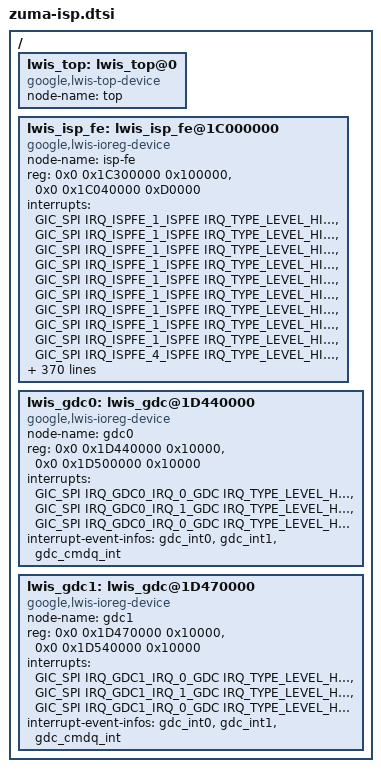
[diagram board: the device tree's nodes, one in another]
// SPDX-License-Identifier: GPL-2.0-only
/*
 * Zuma camera ISP device tree source
 *
 * Copyright 2022 Google LLC.
 */

#include <dt-bindings/interrupt-controller/irq.h>
#include <dt-bindings/interrupt-controller/arm-gic.h>
#include <dt-bindings/interrupt-controller/zuma.h>
#include "zuma-isp-event-info.dtsi"

/ {
	lwis_top: lwis_top@0 {
		compatible = "google,lwis-top-device";

		/* Device node name */
		node-name = "top";
	};

	lwis_isp_fe: lwis_isp_fe@1C000000 {
		compatible = "google,lwis-ioreg-device";

		/* Device node name */
		node-name = "isp-fe";

		/* Register space */
		reg =
			<0x0 0x1C300000 0x100000>, /* ISPFE */
			<0x0 0x1C040000 0xD0000>;  /* CSIS LINK & PHY*/
		reg-names =
			"isp-fe",
			"csis-link-phy";

		interrupts =
			<GIC_SPI IRQ_ISPFE_1_ISPFE IRQ_TYPE_LEVEL_HIGH>
			<GIC_SPI IRQ_ISPFE_1_ISPFE IRQ_TYPE_LEVEL_HIGH>
			<GIC_SPI IRQ_ISPFE_1_ISPFE IRQ_TYPE_LEVEL_HIGH>
			<GIC_SPI IRQ_ISPFE_1_ISPFE IRQ_TYPE_LEVEL_HIGH>
			<GIC_SPI IRQ_ISPFE_1_ISPFE IRQ_TYPE_LEVEL_HIGH>
			<GIC_SPI IRQ_ISPFE_1_ISPFE IRQ_TYPE_LEVEL_HIGH>
			<GIC_SPI IRQ_ISPFE_1_ISPFE IRQ_TYPE_LEVEL_HIGH>
			<GIC_SPI IRQ_ISPFE_1_ISPFE IRQ_TYPE_LEVEL_HIGH>
			<GIC_SPI IRQ_ISPFE_1_ISPFE IRQ_TYPE_LEVEL_HIGH>
			<GIC_SPI IRQ_ISPFE_4_ISPFE IRQ_TYPE_LEVEL_HIGH>
			<GIC_SPI IRQ_ISPFE_4_ISPFE IRQ_TYPE_LEVEL_HIGH>
			<GIC_SPI IRQ_ISPFE_4_ISPFE IRQ_TYPE_LEVEL_HIGH>
			<GIC_SPI IRQ_ISPFE_4_ISPFE IRQ_TYPE_LEVEL_HIGH>
			<GIC_SPI IRQ_ISPFE_4_ISPFE IRQ_TYPE_LEVEL_HIGH>
			<GIC_SPI IRQ_ISPFE_4_ISPFE IRQ_TYPE_LEVEL_HIGH>
			<GIC_SPI IRQ_ISPFE_4_ISPFE IRQ_TYPE_LEVEL_HIGH>
			<GIC_SPI IRQ_ISPFE_4_ISPFE IRQ_TYPE_LEVEL_HIGH>
			<GIC_SPI IRQ_ISPFE_4_ISPFE IRQ_TYPE_LEVEL_HIGH>
			<GIC_SPI IRQ_ISPFE_4_ISPFE IRQ_TYPE_LEVEL_HIGH>
			<GIC_SPI IRQ_ISPFE_4_ISPFE IRQ_TYPE_LEVEL_HIGH>
			<GIC_SPI IRQ_ISPFE_4_ISPFE IRQ_TYPE_LEVEL_HIGH>
			<GIC_SPI IRQ_ISPFE_4_ISPFE IRQ_TYPE_LEVEL_HIGH>
			<GIC_SPI IRQ_ISPFE_4_ISPFE IRQ_TYPE_LEVEL_HIGH>
			<GIC_SPI IRQ_ISPFE_4_ISPFE IRQ_TYPE_LEVEL_HIGH>
			<GIC_SPI IRQ_ISPFE_2_ISPFE IRQ_TYPE_LEVEL_HIGH>
			<GIC_SPI IRQ_ISPFE_2_ISPFE IRQ_TYPE_LEVEL_HIGH>
			<GIC_SPI IRQ_ISPFE_2_ISPFE IRQ_TYPE_LEVEL_HIGH>
			<GIC_SPI IRQ_ISPFE_2_ISPFE IRQ_TYPE_LEVEL_HIGH>
			<GIC_SPI IRQ_ISPFE_2_ISPFE IRQ_TYPE_LEVEL_HIGH>
			<GIC_SPI IRQ_ISPFE_3_ISPFE IRQ_TYPE_LEVEL_HIGH>
			<GIC_SPI IRQ_ISPFE_3_ISPFE IRQ_TYPE_LEVEL_HIGH>
			<GIC_SPI IRQ_ISPFE_3_ISPFE IRQ_TYPE_LEVEL_HIGH>
			<GIC_SPI IRQ_ISPFE_3_ISPFE IRQ_TYPE_LEVEL_HIGH>
			<GIC_SPI IRQ_ISPFE_2_ISPFE IRQ_TYPE_LEVEL_HIGH>
			<GIC_SPI IRQ_ISPFE_0_ISPFE IRQ_TYPE_LEVEL_HIGH>
			<GIC_SPI IRQ_ISPFE_0_ISPFE IRQ_TYPE_LEVEL_HIGH>
			<GIC_SPI IRQ_ISPFE_0_ISPFE IRQ_TYPE_LEVEL_HIGH>
			<GIC_SPI IRQ_ISPFE_0_ISPFE IRQ_TYPE_LEVEL_HIGH>
			<GIC_SPI IRQ_ISPFE_0_ISPFE IRQ_TYPE_LEVEL_HIGH>
			<GIC_SPI IRQ_ISPFE_0_ISPFE IRQ_TYPE_LEVEL_HIGH>
			<GIC_SPI IRQ_ISPFE_0_ISPFE IRQ_TYPE_LEVEL_HIGH>
			<GIC_SPI IRQ_ISPFE_0_ISPFE IRQ_TYPE_LEVEL_HIGH>
			<GIC_SPI IRQ_ISPFE_0_ISPFE IRQ_TYPE_LEVEL_HIGH>
			<GIC_SPI IRQ_ISPFE_0_ISPFE IRQ_TYPE_LEVEL_HIGH>
			<GIC_SPI IRQ_ISPFE_0_ISPFE IRQ_TYPE_LEVEL_HIGH>
			<GIC_SPI IRQ_ISPFE_0_ISPFE IRQ_TYPE_LEVEL_HIGH>
			<GIC_SPI IRQ_ISPFE_0_ISPFE IRQ_TYPE_LEVEL_HIGH>
			<GIC_SPI IRQ_ISPFE_0_ISPFE IRQ_TYPE_LEVEL_HIGH>
			<GIC_SPI IRQ_ISPFE_0_ISPFE IRQ_TYPE_LEVEL_HIGH>
			<GIC_SPI IRQ_ISPFE_0_ISPFE IRQ_TYPE_LEVEL_HIGH>
			<GIC_SPI IRQ_ISPFE_0_ISPFE IRQ_TYPE_LEVEL_HIGH>
			<GIC_SPI IRQ_ISPFE_0_ISPFE IRQ_TYPE_LEVEL_HIGH>
			<GIC_SPI IRQ_ISPFE_0_ISPFE IRQ_TYPE_LEVEL_HIGH>
			<GIC_SPI IRQ_ISPFE_0_ISPFE IRQ_TYPE_LEVEL_HIGH>
			<GIC_SPI IRQ_ISPFE_0_ISPFE IRQ_TYPE_LEVEL_HIGH>
			<GIC_SPI IRQ_ISPFE_0_ISPFE IRQ_TYPE_LEVEL_HIGH>
			<GIC_SPI IRQ_ISPFE_0_ISPFE IRQ_TYPE_LEVEL_HIGH>
			<GIC_SPI IRQ_ISPFE_0_ISPFE IRQ_TYPE_LEVEL_HIGH>
			<GIC_SPI IRQ_ISPFE_0_ISPFE IRQ_TYPE_LEVEL_HIGH>
			<GIC_SPI IRQ_ISPFE_0_ISPFE IRQ_TYPE_LEVEL_HIGH>
			<GIC_SPI IRQ_ISPFE_0_ISPFE IRQ_TYPE_LEVEL_HIGH>
			<GIC_SPI IRQ_ISPFE_0_ISPFE IRQ_TYPE_LEVEL_HIGH>
			<GIC_SPI IRQ_ISPFE_0_ISPFE IRQ_TYPE_LEVEL_HIGH>
			<GIC_SPI IRQ_ISPFE_0_ISPFE IRQ_TYPE_LEVEL_HIGH>
			<GIC_SPI IRQ_ISPFE_0_ISPFE IRQ_TYPE_LEVEL_HIGH>
			<GIC_SPI IRQ_ISPFE_0_ISPFE IRQ_TYPE_LEVEL_HIGH>
			<GIC_SPI IRQ_ISPFE_0_ISPFE IRQ_TYPE_LEVEL_HIGH>
			<GIC_SPI IRQ_ISPFE_0_ISPFE IRQ_TYPE_LEVEL_HIGH>
			<GIC_SPI IRQ_ISPFE_0_ISPFE IRQ_TYPE_LEVEL_HIGH>
			<GIC_SPI IRQ_ISPFE_0_ISPFE IRQ_TYPE_LEVEL_HIGH>
			<GIC_SPI IRQ_ISPFE_0_ISPFE IRQ_TYPE_LEVEL_HIGH>
			<GIC_SPI IRQ_ISPFE_0_ISPFE IRQ_TYPE_LEVEL_HIGH>
			<GIC_SPI IRQ_ISPFE_0_ISPFE IRQ_TYPE_LEVEL_HIGH>
			<GIC_SPI IRQ_ISPFE_0_ISPFE IRQ_TYPE_LEVEL_HIGH>
			<GIC_SPI IRQ_ISPFE_0_ISPFE IRQ_TYPE_LEVEL_HIGH>
			<GIC_SPI IRQ_ISPFE_0_ISPFE IRQ_TYPE_LEVEL_HIGH>
			<GIC_SPI IRQ_ISPFE_0_ISPFE IRQ_TYPE_LEVEL_HIGH>
			<GIC_SPI IRQ_ISPFE_0_ISPFE IRQ_TYPE_LEVEL_HIGH>
			<GIC_SPI IRQ_ISPFE_0_ISPFE IRQ_TYPE_LEVEL_HIGH>
			<GIC_SPI IRQ_ISPFE_0_ISPFE IRQ_TYPE_LEVEL_HIGH>
			<GIC_SPI IRQ_ISPFE_0_ISPFE IRQ_TYPE_LEVEL_HIGH>
			<GIC_SPI IRQ_ISPFE_0_ISPFE IRQ_TYPE_LEVEL_HIGH>
			<GIC_SPI IRQ_ISPFE_0_ISPFE IRQ_TYPE_LEVEL_HIGH>
			<GIC_SPI IRQ_ISPFE_0_ISPFE IRQ_TYPE_LEVEL_HIGH>
			<GIC_SPI IRQ_ISPFE_0_ISPFE IRQ_TYPE_LEVEL_HIGH>
			<GIC_SPI IRQ_ISPFE_0_ISPFE IRQ_TYPE_LEVEL_HIGH>
			<GIC_SPI IRQ_ISPFE_0_ISPFE IRQ_TYPE_LEVEL_HIGH>
			<GIC_SPI IRQ_ISPFE_0_ISPFE IRQ_TYPE_LEVEL_HIGH>
			<GIC_SPI IRQ_ISPFE_0_ISPFE IRQ_TYPE_LEVEL_HIGH>
			<GIC_SPI IRQ_ISPFE_0_ISPFE IRQ_TYPE_LEVEL_HIGH>
			<GIC_SPI IRQ_ISPFE_0_ISPFE IRQ_TYPE_LEVEL_HIGH>
			<GIC_SPI IRQ_ISPFE_0_ISPFE IRQ_TYPE_LEVEL_HIGH>
			<GIC_SPI IRQ_ISPFE_0_ISPFE IRQ_TYPE_LEVEL_HIGH>
			<GIC_SPI IRQ_ISPFE_0_ISPFE IRQ_TYPE_LEVEL_HIGH>
			<GIC_SPI IRQ_ISPFE_0_ISPFE IRQ_TYPE_LEVEL_HIGH>
			<GIC_SPI IRQ_ISPFE_0_ISPFE IRQ_TYPE_LEVEL_HIGH>
			<GIC_SPI IRQ_ISPFE_0_ISPFE IRQ_TYPE_LEVEL_HIGH>
			<GIC_SPI IRQ_ISPFE_0_ISPFE IRQ_TYPE_LEVEL_HIGH>
			<GIC_SPI IRQ_ISPFE_0_ISPFE IRQ_TYPE_LEVEL_HIGH>
			<GIC_SPI IRQ_ISPFE_0_ISPFE IRQ_TYPE_LEVEL_HIGH>
			<GIC_SPI IRQ_ISPFE_0_ISPFE IRQ_TYPE_LEVEL_HIGH>
			<GIC_SPI IRQ_ISPFE_0_ISPFE IRQ_TYPE_LEVEL_HIGH>
			<GIC_SPI IRQ_ISPFE_0_ISPFE IRQ_TYPE_LEVEL_HIGH>
			<GIC_SPI IRQ_ISPFE_0_ISPFE IRQ_TYPE_LEVEL_HIGH>
			<GIC_SPI IRQ_ISPFE_0_ISPFE IRQ_TYPE_LEVEL_HIGH>
			<GIC_SPI IRQ_ISPFE_0_ISPFE IRQ_TYPE_LEVEL_HIGH>
			<GIC_SPI IRQ_ISPFE_0_ISPFE IRQ_TYPE_LEVEL_HIGH>
			<GIC_SPI IRQ_ISPFE_0_ISPFE IRQ_TYPE_LEVEL_HIGH>
			<GIC_SPI IRQ_ISPFE_0_ISPFE IRQ_TYPE_LEVEL_HIGH>
			<GIC_SPI IRQ_ISPFE_0_ISPFE IRQ_TYPE_LEVEL_HIGH>
			<GIC_SPI IRQ_ISPFE_0_ISPFE IRQ_TYPE_LEVEL_HIGH>
			<GIC_SPI IRQ_ISPFE_0_ISPFE IRQ_TYPE_LEVEL_HIGH>
			<GIC_SPI IRQ_ISPFE_0_ISPFE IRQ_TYPE_LEVEL_HIGH>
			<GIC_SPI IRQ_ISPFE_0_ISPFE IRQ_TYPE_LEVEL_HIGH>
			<GIC_SPI IRQ_ISPFE_0_ISPFE IRQ_TYPE_LEVEL_HIGH>
			<GIC_SPI IRQ_ISPFE_0_ISPFE IRQ_TYPE_LEVEL_HIGH>
			<GIC_SPI IRQ_ISPFE_0_ISPFE IRQ_TYPE_LEVEL_HIGH>
			<GIC_SPI IRQ_ISPFE_0_ISPFE IRQ_TYPE_LEVEL_HIGH>
			<GIC_SPI IRQ_ISPFE_0_ISPFE IRQ_TYPE_LEVEL_HIGH>
			<GIC_SPI IRQ_ISPFE_0_ISPFE IRQ_TYPE_LEVEL_HIGH>
			<GIC_SPI IRQ_ISPFE_0_ISPFE IRQ_TYPE_LEVEL_HIGH>
			<GIC_SPI IRQ_ISPFE_0_ISPFE IRQ_TYPE_LEVEL_HIGH>
			<GIC_SPI IRQ_ISPFE_0_ISPFE IRQ_TYPE_LEVEL_HIGH>
			<GIC_SPI IRQ_ISPFE_0_ISPFE IRQ_TYPE_LEVEL_HIGH>
			<GIC_SPI IRQ_ISPFE_0_ISPFE IRQ_TYPE_LEVEL_HIGH>
			<GIC_SPI IRQ_ISPFE_0_ISPFE IRQ_TYPE_LEVEL_HIGH>
			<GIC_SPI IRQ_ISPFE_0_ISPFE IRQ_TYPE_LEVEL_HIGH>
			<GIC_SPI IRQ_ISPFE_0_ISPFE IRQ_TYPE_LEVEL_HIGH>
			<GIC_SPI IRQ_ISPFE_0_ISPFE IRQ_TYPE_LEVEL_HIGH>
			<GIC_SPI IRQ_ISPFE_0_ISPFE IRQ_TYPE_LEVEL_HIGH>
			<GIC_SPI IRQ_ISPFE_0_ISPFE IRQ_TYPE_LEVEL_HIGH>
			<GIC_SPI IRQ_ISPFE_0_ISPFE IRQ_TYPE_LEVEL_HIGH>
			<GIC_SPI IRQ_ISPFE_0_ISPFE IRQ_TYPE_LEVEL_HIGH>
			<GIC_SPI IRQ_ISPFE_0_ISPFE IRQ_TYPE_LEVEL_HIGH>
			<GIC_SPI IRQ_ISPFE_0_ISPFE IRQ_TYPE_LEVEL_HIGH>
			<GIC_SPI IRQ_ISPFE_0_ISPFE IRQ_TYPE_LEVEL_HIGH>
			<GIC_SPI IRQ_ISPFE_0_ISPFE IRQ_TYPE_LEVEL_HIGH>
			<GIC_SPI IRQ_ISPFE_0_ISPFE IRQ_TYPE_LEVEL_HIGH>
			<GIC_SPI IRQ_ISPFE_0_ISPFE IRQ_TYPE_LEVEL_HIGH>
			<GIC_SPI IRQ_ISPFE_0_ISPFE IRQ_TYPE_LEVEL_HIGH>
			<GIC_SPI IRQ_ISPFE_0_ISPFE IRQ_TYPE_LEVEL_HIGH>
			<GIC_SPI IRQ_ISPFE_0_ISPFE IRQ_TYPE_LEVEL_HIGH>
			<GIC_SPI IRQ_ISPFE_0_ISPFE IRQ_TYPE_LEVEL_HIGH>
			<GIC_SPI IRQ_ISPFE_0_ISPFE IRQ_TYPE_LEVEL_HIGH>
			<GIC_SPI IRQ_ISPFE_0_ISPFE IRQ_TYPE_LEVEL_HIGH>
			<GIC_SPI IRQ_ISPFE_0_ISPFE IRQ_TYPE_LEVEL_HIGH>
			<GIC_SPI IRQ_ISPFE_0_ISPFE IRQ_TYPE_LEVEL_HIGH>
			<GIC_SPI IRQ_ISPFE_0_ISPFE IRQ_TYPE_LEVEL_HIGH>
			<GIC_SPI IRQ_ISPFE_0_ISPFE IRQ_TYPE_LEVEL_HIGH>
			<GIC_SPI IRQ_ISPFE_0_ISPFE IRQ_TYPE_LEVEL_HIGH>
			<GIC_SPI IRQ_ISPFE_0_ISPFE IRQ_TYPE_LEVEL_HIGH>
			<GIC_SPI IRQ_ISPFE_0_ISPFE IRQ_TYPE_LEVEL_HIGH>
			<GIC_SPI IRQ_ISPFE_0_ISPFE IRQ_TYPE_LEVEL_HIGH>
			<GIC_SPI IRQ_ISPFE_0_ISPFE IRQ_TYPE_LEVEL_HIGH>
			<GIC_SPI IRQ_CSIS0_ISPFE IRQ_TYPE_LEVEL_HIGH>
			<GIC_SPI IRQ_CSIS1_ISPFE IRQ_TYPE_LEVEL_HIGH>
			<GIC_SPI IRQ_CSIS2_ISPFE IRQ_TYPE_LEVEL_HIGH>
			<GIC_SPI IRQ_CSIS3_ISPFE IRQ_TYPE_LEVEL_HIGH>
			<GIC_SPI IRQ_CSIS4_ISPFE IRQ_TYPE_LEVEL_HIGH>
			<GIC_SPI IRQ_CSIS5_ISPFE IRQ_TYPE_LEVEL_HIGH>
			<GIC_SPI IRQ_CSIS6_ISPFE IRQ_TYPE_LEVEL_HIGH>
			<GIC_SPI IRQ_CSIS7_ISPFE IRQ_TYPE_LEVEL_HIGH>
			<GIC_SPI IRQ_CSIS8_ISPFE IRQ_TYPE_LEVEL_HIGH>
			<GIC_SPI IRQ_CSIS9_ISPFE IRQ_TYPE_LEVEL_HIGH>
			<GIC_SPI IRQ_CSIS10_ISPFE IRQ_TYPE_LEVEL_HIGH>
			<GIC_SPI IRQ_CSIS11_ISPFE IRQ_TYPE_LEVEL_HIGH>
			<GIC_SPI IRQ_CSIS0_ISPFE IRQ_TYPE_LEVEL_HIGH>
			<GIC_SPI IRQ_CSIS1_ISPFE IRQ_TYPE_LEVEL_HIGH>
			<GIC_SPI IRQ_CSIS2_ISPFE IRQ_TYPE_LEVEL_HIGH>
			<GIC_SPI IRQ_CSIS3_ISPFE IRQ_TYPE_LEVEL_HIGH>
			<GIC_SPI IRQ_CSIS4_ISPFE IRQ_TYPE_LEVEL_HIGH>
			<GIC_SPI IRQ_CSIS5_ISPFE IRQ_TYPE_LEVEL_HIGH>
			<GIC_SPI IRQ_CSIS6_ISPFE IRQ_TYPE_LEVEL_HIGH>
			<GIC_SPI IRQ_CSIS7_ISPFE IRQ_TYPE_LEVEL_HIGH>
			<GIC_SPI IRQ_CSIS8_ISPFE IRQ_TYPE_LEVEL_HIGH>
			<GIC_SPI IRQ_CSIS9_ISPFE IRQ_TYPE_LEVEL_HIGH>
			<GIC_SPI IRQ_CSIS10_ISPFE IRQ_TYPE_LEVEL_HIGH>
			<GIC_SPI IRQ_CSIS11_ISPFE IRQ_TYPE_LEVEL_HIGH>
			<GIC_SPI IRQ_CSIS0_ISPFE IRQ_TYPE_LEVEL_HIGH>
			<GIC_SPI IRQ_CSIS1_ISPFE IRQ_TYPE_LEVEL_HIGH>
			<GIC_SPI IRQ_CSIS2_ISPFE IRQ_TYPE_LEVEL_HIGH>
			<GIC_SPI IRQ_CSIS3_ISPFE IRQ_TYPE_LEVEL_HIGH>
			<GIC_SPI IRQ_CSIS4_ISPFE IRQ_TYPE_LEVEL_HIGH>
			<GIC_SPI IRQ_CSIS5_ISPFE IRQ_TYPE_LEVEL_HIGH>
			<GIC_SPI IRQ_CSIS6_ISPFE IRQ_TYPE_LEVEL_HIGH>
			<GIC_SPI IRQ_CSIS7_ISPFE IRQ_TYPE_LEVEL_HIGH>
			<GIC_SPI IRQ_CSIS8_ISPFE IRQ_TYPE_LEVEL_HIGH>
			<GIC_SPI IRQ_CSIS9_ISPFE IRQ_TYPE_LEVEL_HIGH>
			<GIC_SPI IRQ_CSIS10_ISPFE IRQ_TYPE_LEVEL_HIGH>
			<GIC_SPI IRQ_CSIS11_ISPFE IRQ_TYPE_LEVEL_HIGH>
			<GIC_SPI IRQ_CSIS0_ISPFE IRQ_TYPE_LEVEL_HIGH>
			<GIC_SPI IRQ_CSIS1_ISPFE IRQ_TYPE_LEVEL_HIGH>
			<GIC_SPI IRQ_CSIS2_ISPFE IRQ_TYPE_LEVEL_HIGH>
			<GIC_SPI IRQ_CSIS3_ISPFE IRQ_TYPE_LEVEL_HIGH>
			<GIC_SPI IRQ_CSIS4_ISPFE IRQ_TYPE_LEVEL_HIGH>
			<GIC_SPI IRQ_CSIS5_ISPFE IRQ_TYPE_LEVEL_HIGH>
			<GIC_SPI IRQ_CSIS6_ISPFE IRQ_TYPE_LEVEL_HIGH>
			<GIC_SPI IRQ_CSIS7_ISPFE IRQ_TYPE_LEVEL_HIGH>
			<GIC_SPI IRQ_CSIS8_ISPFE IRQ_TYPE_LEVEL_HIGH>
			<GIC_SPI IRQ_CSIS9_ISPFE IRQ_TYPE_LEVEL_HIGH>
			<GIC_SPI IRQ_CSIS10_ISPFE IRQ_TYPE_LEVEL_HIGH>
			<GIC_SPI IRQ_CSIS11_ISPFE IRQ_TYPE_LEVEL_HIGH>;
		interrupt-names =
			"isp_fe_ctx0_fc_bayer",
			"isp_fe_ctx1_fc_bayer",
			"isp_fe_ctx2_fc_bayer",
			"isp_fe_ctx3_fc_bayer",
			"isp_fe_ctx4_fc_bayer",
			"isp_fe_ctx0_fc_pdaf",
			"isp_fe_ctx1_fc_pdaf",
			"isp_fe_ctx2_fc_pdaf",
			"isp_fe_ctx3_fc_pdaf",
			"isp_fe_ctx0_pdma",
			"isp_fe_ctx1_pdma",
			"isp_fe_ctx2_pdma",
			"isp_fe_ctx3_pdma",
			"isp_fe_ctx4_pdma",
			"isp_fe_ctx0_pdma_err",
			"isp_fe_ctx1_pdma_err",
			"isp_fe_ctx2_pdma_err",
			"isp_fe_ctx3_pdma_err",
			"isp_fe_ctx4_pdma_err",
			"isp_fe_ctx0_pdma_rstctl",
			"isp_fe_ctx1_pdma_rstctl",
			"isp_fe_ctx2_pdma_rstctl",
			"isp_fe_ctx3_pdma_rstctl",
			"isp_fe_ctx4_pdma_rstctl",
			"isp_fe_ctx0_lmp_bayer",
			"isp_fe_ctx1_lmp_bayer",
			"isp_fe_ctx2_lmp_bayer",
			"isp_fe_ctx3_lmp_bayer",
			"isp_fe_ctx4_lmp_bayer",
			"isp_fe_ctx0_lmp_pdaf",
			"isp_fe_ctx1_lmp_pdaf",
			"isp_fe_ctx2_lmp_pdaf",
			"isp_fe_ctx3_lmp_pdaf",
			"isp_fe_lmp_debug",
			"isp_fe_csis_core_cmn_ctl",
			"isp_fe_csis_core_ebuf_ctl",
			"isp_fe_loch0_csis_core_img_abort_done",
			"isp_fe_loch1_csis_core_img_abort_done",
			"isp_fe_loch2_csis_core_img_abort_done",
			"isp_fe_loch3_csis_core_img_abort_done",
			"isp_fe_loch4_csis_core_img_abort_done",
			"isp_fe_loch5_csis_core_img_abort_done",
			"isp_fe_loch6_csis_core_img_abort_done",
			"isp_fe_loch0_csis_core_img_proc",
			"isp_fe_loch1_csis_core_img_proc",
			"isp_fe_loch2_csis_core_img_proc",
			"isp_fe_loch3_csis_core_img_proc",
			"isp_fe_loch4_csis_core_img_proc",
			"isp_fe_loch5_csis_core_img_proc",
			"isp_fe_loch6_csis_core_img_proc",
			"isp_fe_loch0_csis_core_img_err",
			"isp_fe_loch1_csis_core_img_err",
			"isp_fe_loch2_csis_core_img_err",
			"isp_fe_loch3_csis_core_img_err",
			"isp_fe_loch4_csis_core_img_err",
			"isp_fe_loch5_csis_core_img_err",
			"isp_fe_loch6_csis_core_img_err",
			"isp_fe_loch0_csis_core_img_mute",
			"isp_fe_loch1_csis_core_img_mute",
			"isp_fe_loch2_csis_core_img_mute",
			"isp_fe_loch3_csis_core_img_mute",
			"isp_fe_loch4_csis_core_img_mute",
			"isp_fe_loch5_csis_core_img_mute",
			"isp_fe_loch6_csis_core_img_mute",
			"isp_fe_loch0_csis_core_pd_abort_done",
			"isp_fe_loch1_csis_core_pd_abort_done",
			"isp_fe_loch2_csis_core_pd_abort_done",
			"isp_fe_loch3_csis_core_pd_abort_done",
			"isp_fe_loch4_csis_core_pd_abort_done",
			"isp_fe_loch5_csis_core_pd_abort_done",
			"isp_fe_loch6_csis_core_pd_abort_done",
			"isp_fe_loch0_csis_core_pd_proc",
			"isp_fe_loch1_csis_core_pd_proc",
			"isp_fe_loch2_csis_core_pd_proc",
			"isp_fe_loch3_csis_core_pd_proc",
			"isp_fe_loch4_csis_core_pd_proc",
			"isp_fe_loch5_csis_core_pd_proc",
			"isp_fe_loch6_csis_core_pd_proc",
			"isp_fe_loch0_csis_core_pd_err",
			"isp_fe_loch1_csis_core_pd_err",
			"isp_fe_loch2_csis_core_pd_err",
			"isp_fe_loch3_csis_core_pd_err",
			"isp_fe_loch4_csis_core_pd_err",
			"isp_fe_loch5_csis_core_pd_err",
			"isp_fe_loch6_csis_core_pd_err",
			"isp_fe_loch0_csis_core_pd_mute",
			"isp_fe_loch1_csis_core_pd_mute",
			"isp_fe_loch2_csis_core_pd_mute",
			"isp_fe_loch3_csis_core_pd_mute",
			"isp_fe_loch4_csis_core_pd_mute",
			"isp_fe_loch5_csis_core_pd_mute",
			"isp_fe_loch6_csis_core_pd_mute",
			"isp_fe_loch0_csis_core_vc_abort_done",
			"isp_fe_loch1_csis_core_vc_abort_done",
			"isp_fe_loch2_csis_core_vc_abort_done",
			"isp_fe_loch3_csis_core_vc_abort_done",
			"isp_fe_loch4_csis_core_vc_abort_done",
			"isp_fe_loch5_csis_core_vc_abort_done",
			"isp_fe_loch6_csis_core_vc_abort_done",
			"isp_fe_loch7_csis_core_vc_abort_done",
			"isp_fe_loch8_csis_core_vc_abort_done",
			"isp_fe_loch9_csis_core_vc_abort_done",
			"isp_fe_loch10_csis_core_vc_abort_done",
			"isp_fe_loch11_csis_core_vc_abort_done",
			"isp_fe_loch12_csis_core_vc_abort_done",
			"isp_fe_loch13_csis_core_vc_abort_done",
			"isp_fe_loch0_csis_core_vc_proc",
			"isp_fe_loch1_csis_core_vc_proc",
			"isp_fe_loch2_csis_core_vc_proc",
			"isp_fe_loch3_csis_core_vc_proc",
			"isp_fe_loch4_csis_core_vc_proc",
			"isp_fe_loch5_csis_core_vc_proc",
			"isp_fe_loch6_csis_core_vc_proc",
			"isp_fe_loch7_csis_core_vc_proc",
			"isp_fe_loch8_csis_core_vc_proc",
			"isp_fe_loch9_csis_core_vc_proc",
			"isp_fe_loch10_csis_core_vc_proc",
			"isp_fe_loch11_csis_core_vc_proc",
			"isp_fe_loch12_csis_core_vc_proc",
			"isp_fe_loch13_csis_core_vc_proc",
			"isp_fe_loch0_csis_core_vc_err",
			"isp_fe_loch1_csis_core_vc_err",
			"isp_fe_loch2_csis_core_vc_err",
			"isp_fe_loch3_csis_core_vc_err",
			"isp_fe_loch4_csis_core_vc_err",
			"isp_fe_loch5_csis_core_vc_err",
			"isp_fe_loch6_csis_core_vc_err",
			"isp_fe_loch7_csis_core_vc_err",
			"isp_fe_loch8_csis_core_vc_err",
			"isp_fe_loch9_csis_core_vc_err",
			"isp_fe_loch10_csis_core_vc_err",
			"isp_fe_loch11_csis_core_vc_err",
			"isp_fe_loch12_csis_core_vc_err",
			"isp_fe_loch13_csis_core_vc_err",
			"isp_fe_loch0_csis_core_vc_mute",
			"isp_fe_loch1_csis_core_vc_mute",
			"isp_fe_loch2_csis_core_vc_mute",
			"isp_fe_loch3_csis_core_vc_mute",
			"isp_fe_loch4_csis_core_vc_mute",
			"isp_fe_loch5_csis_core_vc_mute",
			"isp_fe_loch6_csis_core_vc_mute",
			"isp_fe_loch7_csis_core_vc_mute",
			"isp_fe_loch8_csis_core_vc_mute",
			"isp_fe_loch9_csis_core_vc_mute",
			"isp_fe_loch10_csis_core_vc_mute",
			"isp_fe_loch11_csis_core_vc_mute",
			"isp_fe_loch12_csis_core_vc_mute",
			"isp_fe_loch13_csis_core_vc_mute",
			"isp_fe_ctx0_csis_core_rdma_abort_done",
			"isp_fe_ctx1_csis_core_rdma_abort_done",
			"isp_fe_ctx0_csis_core_rdma_proc",
			"isp_fe_ctx1_csis_core_rdma_proc",
			"isp_fe_ctx0_csis_core_rdma_err",
			"isp_fe_ctx1_csis_core_rdma_err",
			"isp_fe_ctx0_csis_int0",
			"isp_fe_ctx1_csis_int0",
			"isp_fe_ctx2_csis_int0",
			"isp_fe_ctx3_csis_int0",
			"isp_fe_ctx4_csis_int0",
			"isp_fe_ctx5_csis_int0",
			"isp_fe_ctx6_csis_int0",
			"isp_fe_ctx7_csis_int0",
			"isp_fe_ctx8_csis_int0",
			"isp_fe_ctx9_csis_int0",
			"isp_fe_ctx10_csis_int0",
			"isp_fe_ctx11_csis_int0",
			"isp_fe_ctx0_csis_int1",
			"isp_fe_ctx1_csis_int1",
			"isp_fe_ctx2_csis_int1",
			"isp_fe_ctx3_csis_int1",
			"isp_fe_ctx4_csis_int1",
			"isp_fe_ctx5_csis_int1",
			"isp_fe_ctx6_csis_int1",
			"isp_fe_ctx7_csis_int1",
			"isp_fe_ctx8_csis_int1",
			"isp_fe_ctx9_csis_int1",
			"isp_fe_ctx10_csis_int1",
			"isp_fe_ctx11_csis_int1",
			"isp_fe_ctx0_fs_int",
			"isp_fe_ctx1_fs_int",
			"isp_fe_ctx2_fs_int",
			"isp_fe_ctx3_fs_int",
			"isp_fe_ctx4_fs_int",
			"isp_fe_ctx5_fs_int",
			"isp_fe_ctx6_fs_int",
			"isp_fe_ctx7_fs_int",
			"isp_fe_ctx8_fs_int",
			"isp_fe_ctx9_fs_int",
			"isp_fe_ctx10_fs_int",
			"isp_fe_ctx11_fs_int",
			"isp_fe_ctx0_fe_int",
			"isp_fe_ctx1_fe_int",
			"isp_fe_ctx2_fe_int",
			"isp_fe_ctx3_fe_int",
			"isp_fe_ctx4_fe_int",
			"isp_fe_ctx5_fe_int",
			"isp_fe_ctx6_fe_int",
			"isp_fe_ctx7_fe_int",
			"isp_fe_ctx8_fe_int",
			"isp_fe_ctx9_fe_int",
			"isp_fe_ctx10_fe_int",
			"isp_fe_ctx11_fe_int";
		interrupt-event-infos =
			<&isp_fe_ctx0_fc_bayer>,
			<&isp_fe_ctx1_fc_bayer>,
			<&isp_fe_ctx2_fc_bayer>,
			<&isp_fe_ctx3_fc_bayer>,
			<&isp_fe_ctx4_fc_bayer>,
			<&isp_fe_ctx0_fc_pdaf>,
			<&isp_fe_ctx1_fc_pdaf>,
			<&isp_fe_ctx2_fc_pdaf>,
			<&isp_fe_ctx3_fc_pdaf>,
			<&isp_fe_ctx0_pdma>,
			<&isp_fe_ctx1_pdma>,
			<&isp_fe_ctx2_pdma>,
			<&isp_fe_ctx3_pdma>,
			<&isp_fe_ctx4_pdma>,
			<&isp_fe_ctx0_pdma_err>,
			<&isp_fe_ctx1_pdma_err>,
			<&isp_fe_ctx2_pdma_err>,
			<&isp_fe_ctx3_pdma_err>,
			<&isp_fe_ctx4_pdma_err>,
			<&isp_fe_ctx0_pdma_rstctl>,
			<&isp_fe_ctx1_pdma_rstctl>,
			<&isp_fe_ctx2_pdma_rstctl>,
			<&isp_fe_ctx3_pdma_rstctl>,
			<&isp_fe_ctx4_pdma_rstctl>,
			<&isp_fe_ctx0_lmp_bayer>,
			<&isp_fe_ctx1_lmp_bayer>,
			<&isp_fe_ctx2_lmp_bayer>,
			<&isp_fe_ctx3_lmp_bayer>,
			<&isp_fe_ctx4_lmp_bayer>,
			<&isp_fe_ctx0_lmp_pdaf>,
			<&isp_fe_ctx1_lmp_pdaf>,
			<&isp_fe_ctx2_lmp_pdaf>,
			<&isp_fe_ctx3_lmp_pdaf>,
			<&isp_fe_lmp_debug>,
			<&isp_fe_csis_core_cmn_ctl>,
			<&isp_fe_csis_core_ebuf_ctl>,
			<&isp_fe_loch0_csis_core_img_abort_done>,
			<&isp_fe_loch1_csis_core_img_abort_done>,
			<&isp_fe_loch2_csis_core_img_abort_done>,
			<&isp_fe_loch3_csis_core_img_abort_done>,
			<&isp_fe_loch4_csis_core_img_abort_done>,
			<&isp_fe_loch5_csis_core_img_abort_done>,
			<&isp_fe_loch6_csis_core_img_abort_done>,
			<&isp_fe_loch0_csis_core_img_proc>,
			<&isp_fe_loch1_csis_core_img_proc>,
			<&isp_fe_loch2_csis_core_img_proc>,
			<&isp_fe_loch3_csis_core_img_proc>,
			<&isp_fe_loch4_csis_core_img_proc>,
			<&isp_fe_loch5_csis_core_img_proc>,
			<&isp_fe_loch6_csis_core_img_proc>,
			<&isp_fe_loch0_csis_core_img_err>,
			<&isp_fe_loch1_csis_core_img_err>,
			<&isp_fe_loch2_csis_core_img_err>,
			<&isp_fe_loch3_csis_core_img_err>,
			<&isp_fe_loch4_csis_core_img_err>,
			<&isp_fe_loch5_csis_core_img_err>,
			<&isp_fe_loch6_csis_core_img_err>,
			<&isp_fe_loch0_csis_core_img_mute>,
			<&isp_fe_loch1_csis_core_img_mute>,
			<&isp_fe_loch2_csis_core_img_mute>,
			<&isp_fe_loch3_csis_core_img_mute>,
			<&isp_fe_loch4_csis_core_img_mute>,
			<&isp_fe_loch5_csis_core_img_mute>,
			<&isp_fe_loch6_csis_core_img_mute>,
			<&isp_fe_loch0_csis_core_pd_abort_done>,
			<&isp_fe_loch1_csis_core_pd_abort_done>,
			<&isp_fe_loch2_csis_core_pd_abort_done>,
			<&isp_fe_loch3_csis_core_pd_abort_done>,
			<&isp_fe_loch4_csis_core_pd_abort_done>,
			<&isp_fe_loch5_csis_core_pd_abort_done>,
			<&isp_fe_loch6_csis_core_pd_abort_done>,
			<&isp_fe_loch0_csis_core_pd_proc>,
			<&isp_fe_loch1_csis_core_pd_proc>,
			<&isp_fe_loch2_csis_core_pd_proc>,
			<&isp_fe_loch3_csis_core_pd_proc>,
			<&isp_fe_loch4_csis_core_pd_proc>,
			<&isp_fe_loch5_csis_core_pd_proc>,
			<&isp_fe_loch6_csis_core_pd_proc>,
			<&isp_fe_loch0_csis_core_pd_err>,
			<&isp_fe_loch1_csis_core_pd_err>,
			<&isp_fe_loch2_csis_core_pd_err>,
			<&isp_fe_loch3_csis_core_pd_err>,
			<&isp_fe_loch4_csis_core_pd_err>,
			<&isp_fe_loch5_csis_core_pd_err>,
			<&isp_fe_loch6_csis_core_pd_err>,
			<&isp_fe_loch0_csis_core_pd_mute>,
			<&isp_fe_loch1_csis_core_pd_mute>,
			<&isp_fe_loch2_csis_core_pd_mute>,
			<&isp_fe_loch3_csis_core_pd_mute>,
			<&isp_fe_loch4_csis_core_pd_mute>,
			<&isp_fe_loch5_csis_core_pd_mute>,
			<&isp_fe_loch6_csis_core_pd_mute>,
			<&isp_fe_loch0_csis_core_vc_abort_done>,
			<&isp_fe_loch1_csis_core_vc_abort_done>,
			<&isp_fe_loch2_csis_core_vc_abort_done>,
			<&isp_fe_loch3_csis_core_vc_abort_done>,
			<&isp_fe_loch4_csis_core_vc_abort_done>,
			<&isp_fe_loch5_csis_core_vc_abort_done>,
			<&isp_fe_loch6_csis_core_vc_abort_done>,
			<&isp_fe_loch7_csis_core_vc_abort_done>,
			<&isp_fe_loch8_csis_core_vc_abort_done>,
			<&isp_fe_loch9_csis_core_vc_abort_done>,
			<&isp_fe_loch10_csis_core_vc_abort_done>,
			<&isp_fe_loch11_csis_core_vc_abort_done>,
			<&isp_fe_loch12_csis_core_vc_abort_done>,
			<&isp_fe_loch13_csis_core_vc_abort_done>,
			<&isp_fe_loch0_csis_core_vc_proc>,
			<&isp_fe_loch1_csis_core_vc_proc>,
			<&isp_fe_loch2_csis_core_vc_proc>,
			<&isp_fe_loch3_csis_core_vc_proc>,
			<&isp_fe_loch4_csis_core_vc_proc>,
			<&isp_fe_loch5_csis_core_vc_proc>,
			<&isp_fe_loch6_csis_core_vc_proc>,
			<&isp_fe_loch7_csis_core_vc_proc>,
			<&isp_fe_loch8_csis_core_vc_proc>,
			<&isp_fe_loch9_csis_core_vc_proc>,
			<&isp_fe_loch10_csis_core_vc_proc>,
			<&isp_fe_loch11_csis_core_vc_proc>,
			<&isp_fe_loch12_csis_core_vc_proc>,
			<&isp_fe_loch13_csis_core_vc_proc>,
			<&isp_fe_loch0_csis_core_vc_err>,
			<&isp_fe_loch1_csis_core_vc_err>,
			<&isp_fe_loch2_csis_core_vc_err>,
			<&isp_fe_loch3_csis_core_vc_err>,
			<&isp_fe_loch4_csis_core_vc_err>,
			<&isp_fe_loch5_csis_core_vc_err>,
			<&isp_fe_loch6_csis_core_vc_err>,
			<&isp_fe_loch7_csis_core_vc_err>,
			<&isp_fe_loch8_csis_core_vc_err>,
			<&isp_fe_loch9_csis_core_vc_err>,
			<&isp_fe_loch10_csis_core_vc_err>,
			<&isp_fe_loch11_csis_core_vc_err>,
			<&isp_fe_loch12_csis_core_vc_err>,
			<&isp_fe_loch13_csis_core_vc_err>,
			<&isp_fe_loch0_csis_core_vc_mute>,
			<&isp_fe_loch1_csis_core_vc_mute>,
			<&isp_fe_loch2_csis_core_vc_mute>,
			<&isp_fe_loch3_csis_core_vc_mute>,
			<&isp_fe_loch4_csis_core_vc_mute>,
			<&isp_fe_loch5_csis_core_vc_mute>,
			<&isp_fe_loch6_csis_core_vc_mute>,
			<&isp_fe_loch7_csis_core_vc_mute>,
			<&isp_fe_loch8_csis_core_vc_mute>,
			<&isp_fe_loch9_csis_core_vc_mute>,
			<&isp_fe_loch10_csis_core_vc_mute>,
			<&isp_fe_loch11_csis_core_vc_mute>,
			<&isp_fe_loch12_csis_core_vc_mute>,
			<&isp_fe_loch13_csis_core_vc_mute>,
			<&isp_fe_ctx0_csis_core_rdma_abort_done>,
			<&isp_fe_ctx1_csis_core_rdma_abort_done>,
			<&isp_fe_ctx0_csis_core_rdma_proc>,
			<&isp_fe_ctx1_csis_core_rdma_proc>,
			<&isp_fe_ctx0_csis_core_rdma_err>,
			<&isp_fe_ctx1_csis_core_rdma_err>,
			<&isp_fe_ctx0_csis_int0>,
			<&isp_fe_ctx1_csis_int0>,
			<&isp_fe_ctx2_csis_int0>,
			<&isp_fe_ctx3_csis_int0>,
			<&isp_fe_ctx4_csis_int0>,
			<&isp_fe_ctx5_csis_int0>,
			<&isp_fe_ctx6_csis_int0>,
			<&isp_fe_ctx7_csis_int0>,
			<&isp_fe_ctx8_csis_int0>,
			<&isp_fe_ctx9_csis_int0>,
			<&isp_fe_ctx10_csis_int0>,
			<&isp_fe_ctx11_csis_int0>,
			<&isp_fe_ctx0_csis_int1>,
			<&isp_fe_ctx1_csis_int1>,
			<&isp_fe_ctx2_csis_int1>,
			<&isp_fe_ctx3_csis_int1>,
			<&isp_fe_ctx4_csis_int1>,
			<&isp_fe_ctx5_csis_int1>,
			<&isp_fe_ctx6_csis_int1>,
			<&isp_fe_ctx7_csis_int1>,
			<&isp_fe_ctx8_csis_int1>,
			<&isp_fe_ctx9_csis_int1>,
			<&isp_fe_ctx10_csis_int1>,
			<&isp_fe_ctx11_csis_int1>,
			<&isp_fe_ctx0_fs_int>,
			<&isp_fe_ctx1_fs_int>,
			<&isp_fe_ctx2_fs_int>,
			<&isp_fe_ctx3_fs_int>,
			<&isp_fe_ctx4_fs_int>,
			<&isp_fe_ctx5_fs_int>,
			<&isp_fe_ctx6_fs_int>,
			<&isp_fe_ctx7_fs_int>,
			<&isp_fe_ctx8_fs_int>,
			<&isp_fe_ctx9_fs_int>,
			<&isp_fe_ctx10_fs_int>,
			<&isp_fe_ctx11_fs_int>,
			<&isp_fe_ctx0_fe_int>,
			<&isp_fe_ctx1_fe_int>,
			<&isp_fe_ctx2_fe_int>,
			<&isp_fe_ctx3_fe_int>,
			<&isp_fe_ctx4_fe_int>,
			<&isp_fe_ctx5_fe_int>,
			<&isp_fe_ctx6_fe_int>,
			<&isp_fe_ctx7_fe_int>,
			<&isp_fe_ctx8_fe_int>,
			<&isp_fe_ctx9_fe_int>,
			<&isp_fe_ctx10_fe_int>,
			<&isp_fe_ctx11_fe_int>;
	};

	lwis_gdc0: lwis_gdc@1D440000 {
		compatible = "google,lwis-ioreg-device";

		/* Device node name */
		node-name = "gdc0";

		/* Register space */
		reg =
			<0x0 0x1D440000 0x10000>,	/* GDC0 */
			<0x0 0x1D500000 0x10000>;	/* GDC0 SSMT */
		reg-names =
			"gdc",
			"gdc_ssmt";

		interrupts =
			<GIC_SPI IRQ_GDC0_IRQ_0_GDC IRQ_TYPE_LEVEL_HIGH>,
			<GIC_SPI IRQ_GDC0_IRQ_1_GDC IRQ_TYPE_LEVEL_HIGH>,
			<GIC_SPI IRQ_GDC0_IRQ_0_GDC IRQ_TYPE_LEVEL_HIGH>;
		interrupt-names =
			"gdc-int0",
			"gdc-int1",
			"gdc-cmdq-int";
		interrupt-event-infos =
			<&gdc_int0>,
			<&gdc_int1>,
			<&gdc_cmdq_int>;
	};

	lwis_gdc1: lwis_gdc@1D470000 {
		compatible = "google,lwis-ioreg-device";

		/* Device node name */
		node-name = "gdc1";

		/* Register space */
		reg =
			<0x0 0x1D470000 0x10000>,  /* GDC1 */
			<0x0 0x1D540000 0x10000>;  /* GDC1 SSMT */
		reg-names =
			"gdc",
			"gdc_ssmt";

		interrupts =
			<GIC_SPI IRQ_GDC1_IRQ_0_GDC IRQ_TYPE_LEVEL_HIGH>,
			<GIC_SPI IRQ_GDC1_IRQ_1_GDC IRQ_TYPE_LEVEL_HIGH>,
			<GIC_SPI IRQ_GDC1_IRQ_0_GDC IRQ_TYPE_LEVEL_HIGH>;
		interrupt-names =
			"gdc-int0",
			"gdc-int1",
			"gdc-cmdq-int";
		interrupt-event-infos =
			<&gdc_int0>,
			<&gdc_int1>,
			<&gdc_cmdq_int>;
	};
};
